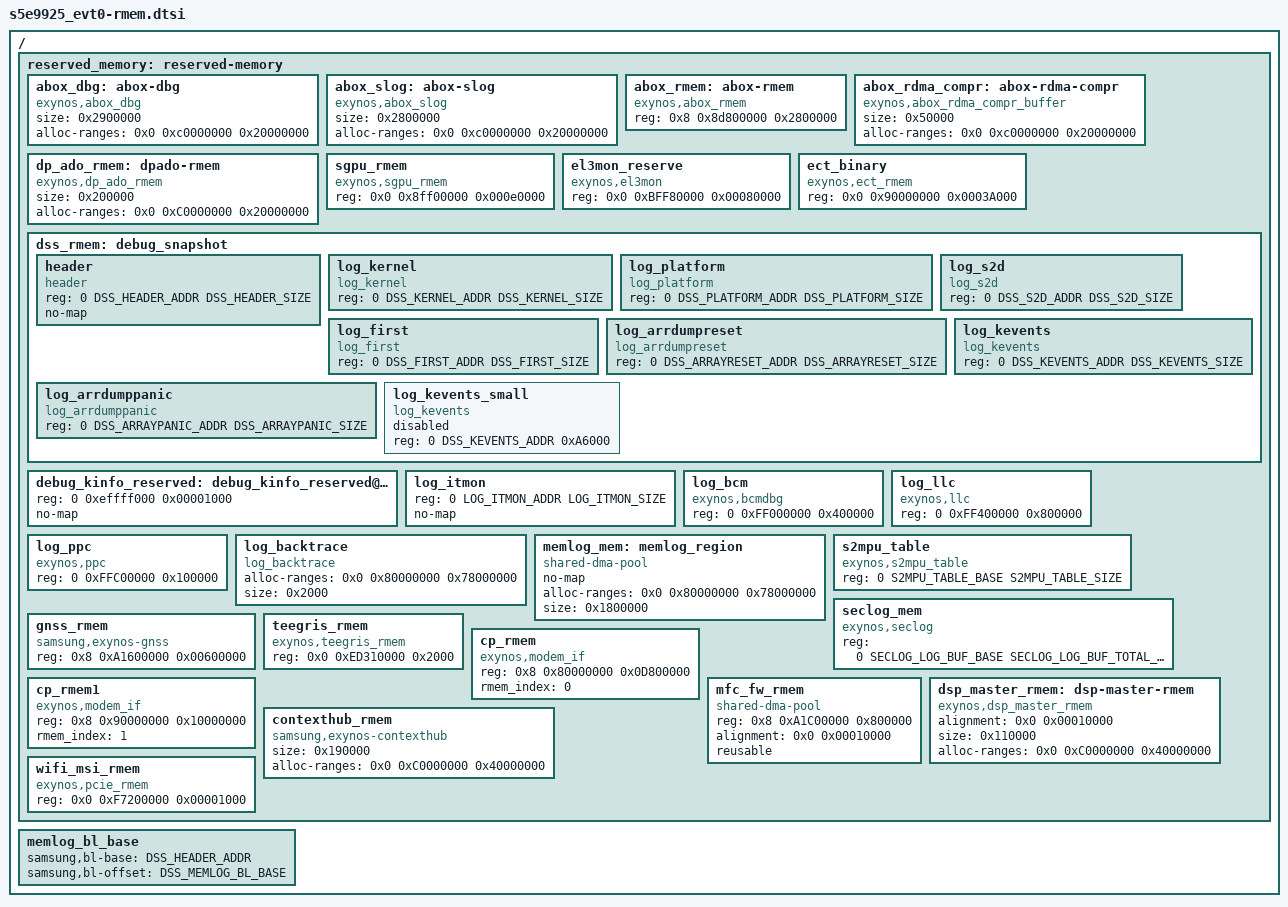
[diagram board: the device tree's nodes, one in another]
/*
 * SAMSUNG EXYNOS device tree source for reserved-memory
 *
 * Copyright (c) 2015 Samsung Electronics Co., Ltd.
 *             http://www.samsung.com
 *
 * This program is free software; you can redistribute it and/or modify
 * it under the terms of the GNU General Public License version 2 as
 * published by the Free Software Foundation.
 */

#include <dt-bindings/soc/samsung/s5e9925-debug.h>
#include <dt-bindings/soc/samsung/s5e9925-s2mpu.h>
#include <dt-bindings/soc/samsung/s5e9925-seclog.h>

/ {
	reserved_memory: reserved-memory {
		#address-cells = <2>;
		#size-cells = <1>;
		ranges;

		abox_dbg: abox-dbg {
			compatible = "exynos,abox_dbg";
			size = <0x2900000>;
			alloc-ranges = <0x0 0xc0000000 0x20000000>;
		};

		abox_slog: abox-slog {
			compatible = "exynos,abox_slog";
			size = <0x2800000>;
			alloc-ranges = <0x0 0xc0000000 0x20000000>;
		};

		abox_rmem: abox-rmem {
			compatible = "exynos,abox_rmem";
			/* Size should be same with
			 * CONFIG_SND_SOC_SAMSUNG_ABOX_DRAM_SIZE.
			 */
			reg = <0x8 0x8d800000 0x2800000>;
		};

		abox_rdma_compr: abox-rdma-compr {
			compatible = "exynos,abox_rdma_compr_buffer";
			size = <0x50000>;
			alloc-ranges = <0x0 0xc0000000 0x20000000>;
		};

		dp_ado_rmem: dpado-rmem {
			compatible = "exynos,dp_ado_rmem";
			size = <0x200000>;
			alloc-ranges = <0x0 0xC0000000 0x20000000>;
		};

		sgpu_rmem: sgpu_rmem {
			compatible = "exynos,sgpu_rmem";
			reg = <0x0 0x8ff00000 0x000e0000>;
		};

		el3mon_reserve {
			compatible = "exynos,el3mon";
			reg = <0x0 0xBFF80000 0x00080000>;
		};

		ect_binary: ect_binary {
			compatible = "exynos,ect_rmem";
			reg = <0x0 0x90000000 0x0003A000>;
		};

                dss_rmem: debug_snapshot {
                        #address-cells = <2>;
                        #size-cells = <1>;
                        header: header {
				compatible = "header";
                                reg = <0 DSS_HEADER_ADDR DSS_HEADER_SIZE>;
				no-map;
                        };
                        log_kernel: log_kernel {
				compatible = "log_kernel";
                                reg = <0 DSS_KERNEL_ADDR DSS_KERNEL_SIZE>;
                        };
			log_platform: log_platform {
				compatible = "log_platform";
				reg = <0 DSS_PLATFORM_ADDR DSS_PLATFORM_SIZE>;
			};
                        log_s2d: log_s2d {
				compatible = "log_s2d";
                                reg = <0 DSS_S2D_ADDR DSS_S2D_SIZE>;
                        };
                        log_first: log_first {
				compatible = "log_first";
				reg = <0 DSS_FIRST_ADDR DSS_FIRST_SIZE>;
                        };
			log_arrdumpreset: log_arrdumpreset {
				compatible = "log_arrdumpreset";
				reg = <0 DSS_ARRAYRESET_ADDR DSS_ARRAYRESET_SIZE>;
			};
			log_arrdumppanic: log_arrdumppanic {
				compatible = "log_arrdumppanic";
				reg = <0 DSS_ARRAYPANIC_ADDR DSS_ARRAYPANIC_SIZE>;
			};
			log_kevents: log_kevents {
				compatible = "log_kevents";
				reg = <0 DSS_KEVENTS_ADDR DSS_KEVENTS_SIZE>;
			};
			log_kevents_small: log_kevents_small {
				compatible = "log_kevents";
				reg = <0 DSS_KEVENTS_ADDR 0xA6000>;
				status = "no";
			};
                };

		debug_kinfo_reserved: debug_kinfo_reserved@effff000 {
			reg = <0 0xeffff000 0x00001000>;
			no-map;
		};

		log_itmon: log_itmon {
			reg = <0 LOG_ITMON_ADDR LOG_ITMON_SIZE>;
			no-map;
		};

		log_bcm: log_bcm {
			compatible = "exynos,bcmdbg";
			reg = <0 0xFF000000 0x400000>;
		};

		log_llc: log_llc {
			compatible = "exynos,llc";
			reg = <0 0xFF400000 0x800000>;
		};

		log_ppc: log_ppc {
			compatible = "exynos,ppc";
			reg = <0 0xFFC00000 0x100000>;
		};

		log_backtrace: log_backtrace {
			compatible = "log_backtrace";
			alloc-ranges = <0x0 0x80000000 0x78000000>;
			size = <0x2000>;
		};

		memlog_mem: memlog_region {
			compatible = "shared-dma-pool";
			no-map;
			alloc-ranges = <0x0 0x80000000 0x78000000>;
			size = <0x1800000>;
		};

		s2mpu_table: s2mpu_table {
			compatible = "exynos,s2mpu_table";
			reg = <0 S2MPU_TABLE_BASE S2MPU_TABLE_SIZE>;
		};

		seclog_mem: seclog_mem {
			compatible = "exynos,seclog";
			reg = <0 SECLOG_LOG_BUF_BASE SECLOG_LOG_BUF_TOTAL_SIZE>;
		};

		gnss_rmem: gnss_rmem {
			compatible = "samsung,exynos-gnss";
			reg = <0x8 0xA1600000 0x00600000>;
		};

		teegris_rmem: teegris_rmem {
			compatible = "exynos,teegris_rmem";
			reg = <0x0 0xED310000 0x2000>;
		};

		cp_rmem: cp_rmem {
			compatible = "exynos,modem_if";
			reg = <0x8 0x80000000 0x0D800000>;
			rmem_index = <0>;
		};

		cp_rmem1: cp_rmem1 {
			compatible = "exynos,modem_if";
			reg = <0x8 0x90000000 0x10000000>;
			rmem_index = <1>;
		};

		mfc_fw_rmem: mfc_fw_rmem {
			compatible = "shared-dma-pool";
			reg = <0x8 0xA1C00000 0x800000>;
			alignment = <0x0 0x00010000>;
			reusable;
		};

		dsp_master_rmem: dsp-master-rmem {
			compatible = "exynos,dsp_master_rmem";
			alignment = <0x0 0x00010000>;
			size = <0x110000>;
			alloc-ranges = <0x0 0xC0000000 0x40000000>;
		};

		contexthub_rmem: contexthub_rmem {
			compatible = "samsung,exynos-contexthub";
			size = <0x190000>;
			alloc-ranges = <0x0 0xC0000000 0x40000000>;
		};

		wifi_msi_rmem: wifi_msi_rmem {
			compatible = "exynos,pcie_rmem";
			reg = <0x0 0xF7200000 0x00001000>;
		};
	};

	memlog_bl_base: memlog_bl_base {
		samsung,bl-base = <DSS_HEADER_ADDR>;
		samsung,bl-offset = <DSS_MEMLOG_BL_BASE>;
	};
};
